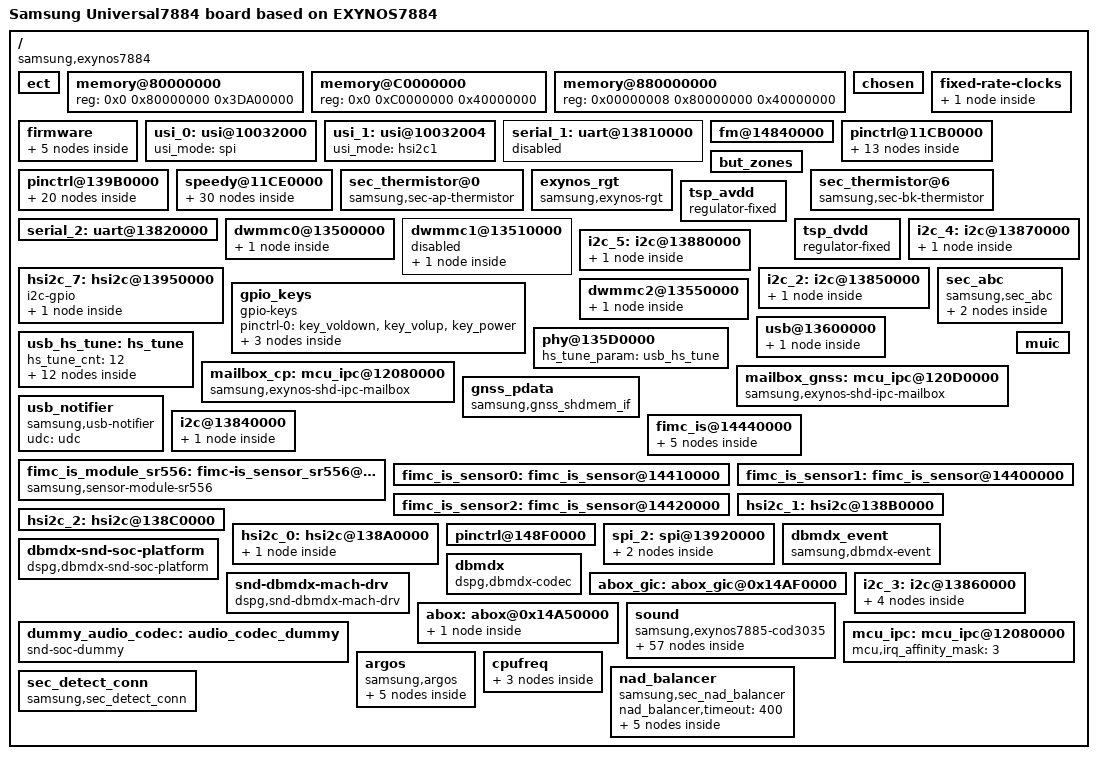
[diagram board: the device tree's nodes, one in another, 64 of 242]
/*
 * SAMSUNG UNIVERSAL7885 board device tree source
 *
 * Copyright (c) 2013 Samsung Electronics Co., Ltd.
 *		http://www.samsung.com
 *
 * This program is free software; you can redistribute it and/or modify
 * it under the terms of the GNU General Public License version 2 as
 * published by the Free Software Foundation.
*/

#include "exynos7884-rmem.dtsi"
#include "exynos7885.dtsi"
#include "display-lcd_gview2_common.dtsi"
#include "modem-s327ap-sipc-pdata.dtsi"
#include "battery_data_gview2lte_common.dtsi"
#include "exynos7885-jackpotlte_motor.dtsi"
#include "exynos7884-mali.dtsi"
/ {
	model = "Samsung Universal7884 board based on EXYNOS7884";
	compatible = "samsung,exynos7884", "samsung,Universal7884";

	ect {
		parameter_address = <0x90000000>;
		parameter_size = <0x19000>;
	};

	memory@80000000 {
		device_type = "memory";
		reg = <0x0 0x80000000 0x3DA00000>;
	};

	memory@C0000000 {
		device_type = "memory";
		reg = <0x0 0xC0000000 0x40000000>;
	};

	memory@880000000 {
		device_type = "memory";
		reg = <0x00000008 0x80000000 0x40000000>;
	};

	chosen {
		bootargs = "console=ram root=/dev/ram0 clk_ignore_unused androidboot.hardware=samsungexynos7885 androidboot.selinux=permissive ess_setup=0x86000000 androidboot.debug_level=0x4948";
		linux,initrd-start = <0x84000000>;
		linux,initrd-end = <0x840FFFFF>;
	};

	fixed-rate-clocks {
		oscclk {
			compatible = "samsung,exynos7885-oscclk";
			clock-frequency = <26000000>;
		};
	};

	firmware {
		android {
			compatible = "android,firmware";
			fstab {
				compatible = "android,fstab";
				system {
					compatible = "android,system";
					dev = "/dev/block/platform/13500000.dwmmc0/by-name/SYSTEM";
					type = "ext4";
					mnt_flags = "ro";
					fsmgr_flags = "wait,verify";
				};
				vendor {
					compatible = "android,vendor";
					dev = "/dev/block/platform/13500000.dwmmc0/by-name/VENDOR";
					type = "ext4";
					mnt_flags = "ro";
					fsmgr_flags = "wait,verify";
				};
				odm {
					compatible = "android,odm";
					dev = "/dev/block/platform/13500000.dwmmc0/by-name/ODM";
					type = "ext4";
					mnt_flags = "ro";
					fsmgr_flags = "wait,verify";
				};
			};
		};
	};

	/* USI MODE SETTINGS

	usi_mode = "hsi2c0" or "hsi2c1" or "spi" or "uart"
	or "hsi2c0_hsi2c1" or "uart_hsi2c1"
	*/
	usi_0: usi@10032000 {
		usi_mode = "spi";
		status = "okay";
	};

	usi_1: usi@10032004 {
		usi_mode = "hsi2c1";
		status = "okay";
	};

	serial_1: uart@13810000 {
		status = "disabled";
	};

	fm@14840000 {
		num-volume-level = <16>;
		val-vol-level = <0 11 16 23 32 45 64
				 90 128 181 256 362
				 512 724 1024 1400>;
	};

	pinctrl@11CB0000 {
		pmic_irq: pmic-irq {
			samsung,pins = "gpa2-0";
			samsung,pin-pud = <3>;
			samsung,pin-drv = <3>;
		};
	};

	pinctrl@139B0000 {
		/* Warm reset information from AP */
		pm_wrsti: pm-wrsti {
			samsung,pins = "gpg1-1";
			samsung,pin-con-pdn = <3>;
		};
	};

	pinctrl@139B0000 {
		/* SPI_FP */
		spi1_bus_inactive: spi1-bus-inactive {
			samsung,pins = "gpp6-0", "gpp6-1", "gpp6-3";
			samsung,pin-function = <1>;
			samsung,pin-pud = <0>;
			samsung,pin-drv = <2>;
		};
		spi1_miso_inactive: spi1-miso-inactive {
			samsung,pins = "gpp6-2";
			samsung,pin-function = <0>;
			samsung,pin-pud = <1>;
			samsung,pin-drv = <2>;
		};
		spi1_clk: spi1-clk {
			samsung,pins = "gpp6-0";
			samsung,pin-function = <2>;
			samsung,pin-pud = <1>;
			samsung,pin-drv = <2>;
		};
		spi1_cs: spi1-cs {
			samsung,pins = "gpp6-1";
			samsung,pin-function = <2>;
			samsung,pin-pud = <3>;
			samsung,pin-drv = <2>;
		};
		spi1_miso: spi1-miso {
			samsung,pins = "gpp6-2";
			samsung,pin-function = <2>;
			samsung,pin-pud = <0>;
			samsung,pin-drv = <2>;
		};
		spi1_mosi: spi1-mosi {
			samsung,pins = "gpp6-3";
			samsung,pin-function = <2>;
			samsung,pin-pud = <1>;
			samsung,pin-drv = <2>;
		};
	};

	but_zones: but_zones {
		#list-but-cells = <3>;
	};

	speedy@11CE0000 {
		status = "okay";
		audio_codec_cod3035x: cod3035x@03 {
			compatible = "codec,cod3035x";
			#sound-dai-cells = <1>;
			reg = <0x03>;
			i2c-speedy-address;
			vdd-supply = <&l36_reg>;
			pinctrl-names = "default";
			mic-bias1-voltage = <3>;
			mic-bias2-voltage = <1>;
			mic-bias-ldo-voltage = <3>;
			use-lassenA;
			use-btn-adc-mode;
			use-det-gdet-adc-mode = <1>;
			jack-imp-tuning = <7>;
			jackout-dbnc-time = <0x02>;
			io-channels = <&exynos_adc 3>,<&exynos_adc 7>;
			io-channel-names = "adc-ear","adc-gdet";
			#io-channel-cells = <1>;
			io-channel-ranges;
			but-zones-list = <&but_zones 226 0 366>,
					 <&but_zones 582 367 433>,
					 <&but_zones 115 434 605>,
					 <&but_zones 114 606 1261>;
			mic-adc-range = <1334>;
			btn-release-value = <1334>;
		};

		s2mpu08mfd@00 {
			compatible = "samsung,s2mpu08mfd";
			acpm-ipc-channel = <2>;
			i2c-speedy-address;
			s2mpu08,wakeup = "enabled";
			s2mpu08,irq-gpio = <&gpa2 0 0>;
			reg = <0x00>;
			interrupts = <2 0 0>;
			interrupt-parent = <&gpa2>;
			pinctrl-names = "default";
			pinctrl-0 = <&pmic_irq &pm_wrsti>;
			/* RTC: wtsr/smpl */
			wtsr_en = "enabled"; /* enable */
			smpl_en = "enabled"; /* enable */
			wtsr_timer_val = <3>;	/* 1000ms */
			smpl_timer_val = <0>;	/* 100ms */
			check_jigon = <0>; /* do not check jigon */
			/* RTC: If it's first boot, reset rtc to 1/1/2018 12:00:00(Mon) */
			init_time,sec = <0>;
			init_time,min = <0>;
			init_time,hour = <12>;
			init_time,mday = <1>;
			init_time,mon = <0>;
			init_time,year = <118>;
			init_time,wday = <1>;

			samsung,codec-interrupt = <&audio_codec_cod3035x>;

			regulators {
				b1_reg: BUCK1 {
					regulator-name = "vdd_mif";
					regulator-min-microvolt = <500000>;
					regulator-max-microvolt = <1100000>;
					regulator-always-on;
					regulator-ramp-delay = <12000>;
					regulator-initial-mode = <2>;
				};

				b2_reg: BUCK2 {
					regulator-name = "vdd_cpucl0";
					regulator-min-microvolt = <500000>;
					regulator-max-microvolt = <1300000>;
					regulator-always-on;
					regulator-ramp-delay = <12000>;
					regulator-initial-mode = <1>;
				};

				b3_reg: BUCK3 {
					regulator-name = "vdd_cpucl1_2";
					regulator-min-microvolt = <500000>;
					regulator-max-microvolt = <1300000>;
					regulator-always-on;
					regulator-ramp-delay = <12000>;
					regulator-initial-mode = <1>;
				};

				b4_reg: BUCK4 {
					regulator-name = "vdd_int";
					regulator-min-microvolt = <500000>;
					regulator-max-microvolt = <1200000>;
					regulator-always-on;
					regulator-ramp-delay = <12000>;
					regulator-initial-mode = <2>;
				};

				b5_reg: BUCK5 {
					regulator-name = "vdd_g3d";
					regulator-min-microvolt = <500000>;
					regulator-max-microvolt = <1300000>;
					regulator-always-on;
					regulator-ramp-delay = <12000>;
					regulator-initial-mode = <1>;
				};

				b6_reg: BUCK6 {
					regulator-name = "vdd2_mem";
					regulator-min-microvolt = <500000>;
					regulator-max-microvolt = <1300000>;
					regulator-always-on;
					regulator-ramp-delay = <12000>;
					regulator-initial-mode = <3>;
				};

				b7_reg: BUCK7 {
					regulator-name = "vdd_lldo";
					regulator-min-microvolt = <1200000>;
					regulator-max-microvolt = <1500000>;
					regulator-always-on;
					regulator-boot-on;
					regulator-ramp-delay = <12000>;
					regulator-initial-mode = <3>;
				};

				b8_reg: BUCK8 {
					regulator-name = "vdd_mldo";
					regulator-min-microvolt = <1800000>;
					regulator-max-microvolt = <2100000>;
					regulator-always-on;
					regulator-ramp-delay = <12000>;
					regulator-initial-mode = <3>;
				};

				l1_reg: LDO1 {
					regulator-name = "vdd_ldo1";
					regulator-min-microvolt = <700000>;
					regulator-max-microvolt = <1300000>;
					regulator-always-on;
					regulator-ramp-delay = <12000>;
					regulator-initial-mode = <3>;
				};

				l2_reg: LDO2 {
					regulator-name = "vqmmc";
					regulator-min-microvolt = <1800000>;
					regulator-max-microvolt = <3375000>;
					regulator-ramp-delay = <12000>;
				};

				l3_reg: LDO3 {
					regulator-name = "vdd_ldo3";
					regulator-min-microvolt = <800000>;
					regulator-max-microvolt = <1950000>;
					regulator-always-on;
					regulator-ramp-delay = <12000>;
					regulator-initial-mode = <3>;
				};

				l4_reg: LDO4 {
					regulator-name = "vdd_ldo4";
					regulator-min-microvolt = <500000>;
					regulator-max-microvolt = <1300000>;
					regulator-always-on;
					regulator-ramp-delay = <12000>;
					regulator-initial-mode = <1>;
				};

				l5_reg: LDO5 {
					regulator-name = "vdd_ldo5";
					regulator-min-microvolt = <800000>;
					regulator-max-microvolt = <1350000>;
					regulator-always-on;
					regulator-ramp-delay = <12000>;
					regulator-initial-mode = <1>;
				};

				l6_reg: LDO6 {
					regulator-name = "vdd_ldo6";
					regulator-min-microvolt = <800000>;
					regulator-max-microvolt = <1350000>;
					regulator-always-on;
					regulator-ramp-delay = <12000>;
					regulator-initial-mode = <1>;
				};

				l7_reg: LDO7 {
					regulator-name = "vdd_ldo7";
					regulator-min-microvolt = <800000>;
					regulator-max-microvolt = <1950000>;
					regulator-always-on;
					regulator-ramp-delay = <12000>;
					regulator-initial-mode = <1>;
				};

				l8_reg: LDO8 {
					regulator-name = "vdd_ldo8";
					regulator-min-microvolt = <500000>;
					regulator-max-microvolt = <1300000>;
					regulator-always-on;
					regulator-ramp-delay = <12000>;
					regulator-initial-mode = <1>;
				};

				l9_reg: LDO9 {
					regulator-name = "vdd_ldo9";
					regulator-min-microvolt = <500000>;
					regulator-max-microvolt = <1300000>;
					regulator-always-on;
					regulator-ramp-delay = <12000>;
					regulator-initial-mode = <1>;
				};

				l10_reg: LDO10 {
					regulator-name = "vdd_ldo10";
					regulator-min-microvolt = <500000>;
					regulator-max-microvolt = <1300000>;
					regulator-always-on;
					regulator-ramp-delay = <12000>;
					regulator-initial-mode = <1>;
				};

				l11_reg: LDO11 {
					regulator-name = "vdd_ldo11";
					regulator-min-microvolt = <500000>;
					regulator-max-microvolt = <1300000>;
					regulator-always-on;
					regulator-ramp-delay = <12000>;
					regulator-initial-mode = <1>;
				};

				l12_reg: LDO12 {
					regulator-name = "vdd_ldo12";
					regulator-min-microvolt = <800000>;
					regulator-max-microvolt = <1350000>;
					regulator-always-on;
					regulator-ramp-delay = <12000>;
					regulator-initial-mode = <1>;
				};

				l13_reg: LDO13 {
					regulator-name = "vdd_ldo13";
					regulator-min-microvolt = <800000>;
					regulator-max-microvolt = <1950000>;
					regulator-always-on;
					regulator-ramp-delay = <12000>;
					regulator-initial-mode = <1>;
				};

				l14_reg: LDO14 {
					regulator-name = "vdd_ldo14";
					regulator-min-microvolt = <1800000>;
					regulator-max-microvolt = <3375000>;
					regulator-always-on;
					regulator-ramp-delay = <12000>;
					regulator-initial-mode = <1>;
				};

				l33_reg: LDO33 {
					regulator-name = "vdd_ldo33";
					regulator-min-microvolt = <800000>;
					regulator-max-microvolt = <1950000>;
					regulator-always-on;
					regulator-ramp-delay = <12000>;
					regulator-initial-mode = <3>;
				};

				l34_reg: LDO34 {
					regulator-name = "vdd_ldo34";
					regulator-min-microvolt = <1800000>;
					regulator-max-microvolt = <3375000>;
					regulator-always-on;
					regulator-ramp-delay = <12000>;
					regulator-initial-mode = <3>;
				};

				l35_reg: LDO35 {
					regulator-name = "vmmc";
					regulator-min-microvolt = <1800000>;
					regulator-max-microvolt = <3000000>;
					regulator-ramp-delay = <12000>;
				};

				l36_reg: LDO36 {
					regulator-name = "vdd_ldo36";
					regulator-min-microvolt = <800000>;
					regulator-max-microvolt = <1950000>;
					regulator-always-on;
					regulator-ramp-delay = <12000>;
					regulator-initial-mode = <3>;
				};

				l37_reg: LDO37 {
					regulator-name = "vdd_ldo37";
					regulator-min-microvolt = <1800000>;
					regulator-max-microvolt = <3375000>;
					regulator-always-on;
					regulator-ramp-delay = <12000>;
					regulator-initial-mode = <3>;
				};
			};
		};
	};

	sec_thermistor@0 {
		compatible = "samsung,sec-ap-thermistor";
		status = "okay";

		adc_array = <165 173 181 189 197 205 213 221 229 237
			245 259 273 287 301 315 335 355 375 395
			415 437 459 482 504 527 546 565 584 603
			623 643 663 683 704 724 748 772 797 821
			845 874 904 933 962 992 1025 1059 1092 1126
			1159 1198 1236 1275 1313 1352 1389 1427 1464 1502
			1540 1583 1626 1669 1712 1756 1796 1836 1876 1916
			1956 1997 2038 2078 2119 2160 2204 2248 2292 2336
			2380 2420 2460 2499 2539 2579 2613 2646 2680 2714
			2748 2785 2822 2859 2896 2933 2965 2996 3028 3059
			3091 3119 3147 3175 3203 3231 3247 3263 3279 3295
			3311>;
		temp_array = <900 890 880 870 860 850 840 830 820 810
			800 790 780 770 760 750 740 730 720 710
			700 690 680 670 660 650 640 630 620 610
			600 590 580 570 560 550 540 530 520 510
			500 490 480 470 460 450 440 430 420 410
			400 390 380 370 360 350 340 330 320 310
			300 290 280 270 260 250 240 230 220 210
			200 190 180 170 160 150 140 130 120 110
			100 90 80 70 60 50 40 30 20 10
			0 (-10) (-20) (-30) (-40) (-50) (-60) (-70) (-80) (-90)
			(-100) (-110) (-120) (-130) (-140) (-150) (-160) (-170) (-180) (-190)
			(-200)>;
		io-channels = <&exynos_adc 0>;
		io-channel-names = "adc-ap-temp";
		io-channel-ranges;
	};

	sec_thermistor@6 {
		compatible = "samsung,sec-bk-thermistor";
		status = "okay";

		adc_array = <324 332 340 348 356 364 372 380 388 396
			404 418 432 446 460 474 494 514 534 554
			574 595 616 638 659 681 704 727 750 774
			797 821 845 869 893 918 945 973 1001 1028
			1056 1088 1120 1152 1184 1216 1254 1292 1330 1368
			1407 1447 1488 1529 1569 1610 1650 1690 1729 1769
			1809 1855 1900 1946 1991 2037 2078 2120 2161 2202
			2244 2286 2329 2371 2414 2457 2500 2543 2586 2629
			2672 2710 2749 2787 2826 2864 2895 2927 2958 2990
			3021 3055 3088 3122 3156 3190 3217 3245 3272 3300
			3328 3352 3376 3400 3424 3448 3461 3474 3487 3501
			3514>;
		temp_array = <900 890 880 870 860 850 840 830 820 810
			800 790 780 770 760 750 740 730 720 710
			700 690 680 670 660 650 640 630 620 610
			600 590 580 570 560 550 540 530 520 510
			500 490 480 470 460 450 440 430 420 410
			400 390 380 370 360 350 340 330 320 310
			300 290 280 270 260 250 240 230 220 210
			200 190 180 170 160 150 140 130 120 110
			100 90 80 70 60 50 40 30 20 10
			0 (-10) (-20) (-30) (-40) (-50) (-60) (-70) (-80) (-90)
			(-100) (-110) (-120) (-130) (-140) (-150) (-160) (-170) (-180) (-190)
			(-200)>;
		io-channels = <&exynos_adc 6>;
		io-channel-names = "adc-bk-temp";
		io-channel-ranges;
	};

	exynos_rgt {
		compatible = "samsung,exynos-rgt";
	};

	serial_2: uart@13820000 {
		status = "okay";
	};

	pinctrl@11CB0000 {
		dwmmc2_cd_ext_irq: dwmmc2_cd_ext_irq {
			samsung,pins = "gpa0-7";
			samsung,pin-function = <0xf>;
			samsung,pin-pud = <0>;
			samsung,pin-drv = <3>;
		};
	};

	dwmmc0@13500000 {
		status = "okay";
		num-slots = <1>;
		broken-cd;
		fixed_voltage;
		supports-highspeed;
		mmc-ddr-1_8v;
		mmc-hs200-1_8v;
		mmc-hs400-1_8v;
		supports-8bit;
		supports-cmd23;
		supports-erase;
		supports-hs400-enhanced-strobe;
		card-init-hwacg-ctrl;
		support-cmdq;
		qos-dvfs-level = <100000>;
		fifo-depth = <0x40>;
		non-removable;
		desc-size = <4>;
		card-detect-delay = <200>;
		samsung,dw-mshc-ciu-div = <3>;
		samsung,dw-mshc-txdt-crc-timer-fastlimit = <0x13>;
		samsung,dw-mshc-txdt-crc-timer-initval = <0x15>;
		samsung,dw-mshc-hs400-delay-line = <0x60>;
		samsung,dw-mshc-sdr-timing = <3 0 4 0>;
		samsung,dw-mshc-ddr-timing = <3 0 4 2>;
		samsung,dw-mshc-hs200-timing = <3 0 3 0>;
		samsung,dw-mshc-hs400-timing = <1 0 2 0>;
		samsung,dw-mshc-hs400-ulp-timing = <3 0 2 0>;

		num-ref-clks = <12>;
		ciu_clkin = <25 50 50 25 50 100 200 50 50 200 200 200>;

		/* Swapping clock drive strength */
		clk-drive-number = <4>;
		pinctrl-names = "default",
			"fast-slew-rate-1x",
			"fast-slew-rate-2x",
			"fast-slew-rate-3x",
			"fast-slew-rate-4x";
		pinctrl-0 = <&sd0_clk &sd0_cmd &sd0_rdqs &sd0_bus1 &sd0_bus4 &sd0_bus8>;
		pinctrl-1 = <&sd0_clk_fast_slew_rate_1x>;
		pinctrl-2 = <&sd0_clk_fast_slew_rate_2x>;
		pinctrl-3 = <&sd0_clk_fast_slew_rate_3x>;
		pinctrl-4 = <&sd0_clk_fast_slew_rate_4x>;
		slot@0 {
			reg = <0>;
			bus-width = <8>;
		};

	};

	dwmmc1@13510000 {
		status = "disabled";
		num-slots = <1>;
		channel = <1>;
		fixed_voltage;
		enable-cclk-on-suspend;
		caps-control;
		supports-highspeed;
		supports-4bit;
		keep-power-in-suspend;
		pm-ignore-notify;
		card-detect-type-external;
		use-broken-voltage;
		fifo-depth = <0x40>;
		card-detect-delay = <200>;
		qos-dvfs-level = <100000>;
		data-timeout = <200>;
		hto-timeout = <80>;
		samsung,dw-mshc-ciu-div = <3>;
		samsung,dw-mshc-sdr-timing = <3 0 2 0>;
		samsung,dw-mshc-ddr-timing = <3 0 2 1>;
		samsung,dw-mshc-sdr50-timing = <3 0 4 2>;
		samsung,dw-mshc-sdr104-timing = <3 0 3 0>;

		num-ref-clks = <9>;
		ciu_clkin = <25 50 50 25 50 100 200 50 50>;

		clk-drive-number = <4>;
		pinctrl-names = "default",
			"fast-slew-rate-1x",
			"fast-slew-rate-2x",
			"fast-slew-rate-3x",
			"fast-slew-rate-4x";
		pinctrl-0 = <&sd1_clk &sd1_cmd &sd1_bus1 &sd1_bus4>;
		pinctrl-1 = <&sd1_clk_fast_slew_rate_1x>;
		pinctrl-2 = <&sd1_clk_fast_slew_rate_2x>;
		pinctrl-3 = <&sd1_clk_fast_slew_rate_3x>;
		pinctrl-4 = <&sd1_clk_fast_slew_rate_4x>;
		slot@0 {
			reg = <0>;
			bus-width = <4>;
		};
	};

	tsp_avdd {
		compatible = "regulator-fixed";
		regulator-name = "tsp_avdd";
		regulator-min-microvolt = <1800000>;
		regulator-max-microvolt = <1800000>;
		gpio = <&gpg3 0 0>;
		enable-active-high;
		regulator-boot-on;
	};

	tsp_dvdd {
		compatible = "regulator-fixed";
		regulator-name = "tsp_dvdd";
		regulator-min-microvolt = <1800000>;
		regulator-max-microvolt = <1800000>;
		gpio = <&gpg3 3 0>;
		enable-active-high;
		regulator-boot-on;
	};

	i2c_4: i2c@13870000 {
		samsung,i2c-sda-delay = <100>;
		samsung,i2c-max-bus-freq = <400000>;
		status = "okay";
		touchscreen@49 {
			compatible = "stm,fts_touch";
			reg = <0x49>;
			pinctrl-names = "on_state", "off_state";
			pinctrl-0 = <&attn_irq>;
			pinctrl-1 = <&attn_input>;
			stm,irq_gpio = <&gpa0 0 0>;
			stm,irq_type = <8200>;
			stm,max_coords = <1920 1080>;	/* x y */
			stm,project_name = "view2", "T395";
			stm,regulator_dvdd = "tsp_dvdd";
			stm,regulator_avdd = "tsp_avdd";
			stm,firmware_name = "tsp_stm/fts6ct108_view2.fw";
			stm,factory_item_version = <2>;
			stm,tclm_level = <2>;
			stm,afe_base = <0x040B>;
		};
	};

	pinctrl@11CB0000 {
		attn_irq: attn-irq {
			samsung,pins = "gpa0-0";
			samsung,pin-function = <0xf>;
			samsung,pin-pud = <0>;
			samsung,pin-drv = <0>;
		};
		attn_input: attn-input {
			samsung,pins = "gpa0-0";
			samsung,pin-function = <0>;
			samsung,pin-pud = <1>;
		};
	};

	pinctrl@11CB0000 {
		main_grip1_int: main-grip1-int {
			samsung,pins = "gpa1-2";
			samsung,pin-function = <0xf>;
			samsung,pin-pud = <0>;
			samsung,pin-drv = <0>;
		};
	};

	pinctrl@139B0000 {
		sensor_en: sensor-en {
			samsung,pins = "gpg1-0";
			samsung,pin-function = <1>;
			samsung,pin-pud = <0>;
			samsung,pin-val = <1>;
			samsung,pin-drv = <0>;
		};

		acc_en: acc-en {
			samsung,pins = "gpg1-3";
			samsung,pin-function = <1>;
			samsung,pin-pud = <0>;
			samsung,pin-val = <1>;
			samsung,pin-drv = <0>;
		};

		grip_ldo: grip-ldo {
			samsung,pins = "gpp6-4";
			samsung,pin-function = <1>;
			samsung,pin-pud = <0>;
		};

		cfg_i2c: cfg-i2c {
			samsung,pins = "gpp4-2", "gpp4-3";
			samsung,pin-function = <2>;
			samsung,pin-pud = <0>;
			samsung,pin-drv = <0>;
		};

		acc_i2c: acc-i2c {
			samsung,pins = "gpp2-0", "gpp2-1";
			samsung,pin-function = <2>;
			samsung,pin-pud = <0>;
			samsung,pin-drv = <0>;
		};

		light_i2c: light-i2c {
			samsung,pins = "gpc2-6", "gpc2-7";
			samsung,pin-function = <2>;
			samsung,pin-pud = <0>;
			samsung,pin-drv = <0>;
		};
	};

	i2c_5:i2c@13880000 {
		status = "okay";
		#address-cells = <1>;
		#size-cells = <0>;
		samsung,i2c-sda-delay = <100>;
		pinctrl-names = "default";
		pinctrl-0 = <&cfg_i2c>;

		a96t3x6@20 {
			compatible = "a96t3x6";
			pinctrl-names = "default", "grip_ldo";
			pinctrl-0 = <&main_grip1_int &grip_ldo>;
			reg = <0x20>;
			interrupt-parent = <&gpa1>;
			interrupts = <2 0 0>;
			a96t3x6,irq_gpio = <&gpa1 2 0>;
			a96t3x6,ldo_en = <&gpp6 4 0>;
			/* temporary firmware */
			a96t3x6,fw_path = "abov/a96t346_gview2lte.fw";
			a96t3x6,firmup_cmd = <0x38>;
		};
	};

	hsi2c_7: hsi2c@13950000{
		compatible = "i2c-gpio";
		gpios = <&gpc2 6 0 /* sda */
                 &gpc2 7 0 /* scl */>;
		i2c-gpio,delay-us = <2>;
		status = "okay";
		#address-cells = <1>;
		#size-cells = <0>;
		pinctrl-names = "default", "sensor_en";
		pinctrl-0 = <&light_i2c &sensor_en>;

		cm3323-i2c@10 {
			compatible = "cm3323-i2c";
			reg = <0x10>;
			/* cm3323-i2c,vdd-supply = <>; */
			cm3323-i2c,vdd-alwayson = <1>;
			cm3323-i2c,vdd-ldo= <&gpg1 0 0x01>; /* SENSOR_LDO_EN */
		};
	};

	i2c_2: i2c@13850000 {
		samsung,i2c-sda-delay = <100>;
		samsung,i2c-max-bus-freq = <400000>;
		status = "okay";
		#address-cells = <1>;
		#size-cells = <0>;
		pinctrl-names = "default";
		pinctrl-0 = <&acc_i2c>;

		lis2ds@1D {
			compatible = "st,lis2ds";
			reg = <0x1D>;
			pinctrl-names = "default";
			pinctrl-0 = <&acc_int>;
			interrupt-parent = <&gpa0>;
			interrupts = <3 0 0>;
			st,orientation = <1 2 1 0 1 1 1 1 0>;
			st,drdy-int-pin = <1>;
			st,irq_gpio = <&gpa0 3 0x00>;
			st,vdd_ldo_pin = <&gpg1 3 0x01>; /* ACC_LDO_EN */
		};
	};

	dwmmc2@13550000 {
		status = "okay";
		num-slots = <1>;
		supports-4bit;
		supports-cmd23;
		supports-erase;
		supports-highspeed;
		sd-uhs-sdr50;
		sd-uhs-sdr104;
		card-detect-gpio;
		card-no-pre-powerup;
		bypass-for-allpass;
		card-init-hwacg-ctrl;
		skip-init-mmc-scan;
		qos-dvfs-level = <100000>;
		qos-sd3-dvfs-level = <267000>;
		fifo-depth = <0x40>;
		desc-size = <4>;
		card-detect-delay = <200>;
		data-timeout = <200>;
		hto-timeout = <80>;
		samsung,dw-mshc-ciu-div = <3>;
		clock-frequency = <800000000>;
		samsung,dw-mshc-sdr-timing = <3 0 2 0>;
		samsung,dw-mshc-ddr-timing = <3 0 2 1>;
		samsung,dw-mshc-sdr50-timing = <3 0 4 2>;
		samsung,dw-mshc-sdr104-timing = <3 0 3 0>;

		num-ref-clks = <9>;
		ciu_clkin = <25 50 50 25 50 100 200 50 50>;

		/* Swapping clock drive strength */
		clk-drive-number = <4>;
		pinctrl-names = "default",
			"fast-slew-rate-1x",
			"fast-slew-rate-2x",
			"fast-slew-rate-3x",
			"fast-slew-rate-4x";
		pinctrl-0 = <&sd2_clk &sd2_cmd &sd2_bus1 &sd2_bus4 &dwmmc2_cd_ext_irq>;
		pinctrl-1 = <&sd2_clk_fast_slew_rate_1x>;
		pinctrl-2 = <&sd2_clk_fast_slew_rate_2x>;
		pinctrl-3 = <&sd2_clk_fast_slew_rate_3x>;
		pinctrl-4 = <&sd2_clk_fast_slew_rate_4x>;

		card-detect = <&gpa0 7 0xf>;
		sec-sd-slot-type = <2>; /* Hybrid Tray SD slot */

		slot@0 {
			reg = <0>;
			bus-width = <4>;
			disable-wp;
		};

	};

	pinctrl@11CB0000 {
		key_power: key-power {
			samsung,pins = "gpa1-7";
			samsung,pin-function = <0xf>;
			samsung,pin-pud = <0>;
			samsung,pin-drv = <0>;
		};

		key_voldown: key-voldown {
			samsung,pins = "gpa1-6";
			samsung,pin-function = <0xf>;
			samsung,pin-pud = <0>;
			samsung,pin-drv = <0>;
		};

		key_volup: key-volup {
			samsung,pins = "gpa1-5";
			samsung,pin-function = <0xf>;
			samsung,pin-pud = <0>;
			samsung,pin-drv = <0>;
		};
	};

	gpio_keys {
		status = "okay";
		compatible = "gpio-keys";
		#address-cells = <1>;
		#size-cells = <0>;
		pinctrl-names = "default";
		pinctrl-0 = <&key_voldown &key_volup &key_power>;
		button@1 {
			label = "gpio-keys: KEY_VOLUMEDOWN";
			interrupts = <6 0 0>;
			interrupt-parent = <&gpa1>;
			linux,code = <114>;
			gpios = <&gpa1 6 0xf>;
		};
		button@2 {
			label = "gpio-keys: KEY_VOLUMEUP";
			interrupts = <5 0 0>;
			interrupt-parent = <&gpa1>;
			linux,code = <115>;
			gpios = <&gpa1 5 0xf>;
		};
		button@3 {
			label = "gpio-keys: KEY_POWER";
			interrupts = <7 0 0>;
			interrupt-parent = <&gpa1>;
			linux,code = <116>;
			gpios = <&gpa1 7 0xf>;
			gpio-key,wakeup = <1>;
		};

	};

	sec_abc {
		compatible = "samsung,sec_abc";
		status = "okay";

		gpu {
			gpu,label="GPU fault";
			gpu,threshold_count=<20>;
			gpu,threshold_time=<1200>;
		};
		aicl {
			aicl,label="battery aicl";
			aicl,threshold_count=<5>;
			aicl,threshold_time=<300>;
		};
	};

	usb@13600000 {
		status = "okay";
		dwc3 {
			dr_mode = "otg";
			maximum-speed = "high-speed";
			snps,quirk-frame-length-adjustment = <0x20>;
		};
	};

	phy@135D0000 {
		status = "okay";
		hs_tune_param = <&usb_hs_tune>;
	};

	usb_hs_tune:hs_tune {
		hs_tune_cnt = <12>;

		/* value = <device host> */
		hs_tune1 {
			tune_name = "tx_vref";
			tune_value = <0xd 0x1>;
		};

		hs_tune2 {
			tune_name = "tx_pre_emp";
			tune_value = <0x3 0x3>;
		};

		hs_tune3 {
			tune_name = "tx_pre_emp_plus";
			tune_value = <0x0 0x0>;
		};

		hs_tune4 {
			tune_name = "tx_res";
			tune_value = <0x3 0x3>;
		};

		hs_tune5 {
			tune_name = "tx_rise";
			tune_value = <0x3 0x3>;
		};

		hs_tune6 {
			tune_name = "tx_hsxv";
			tune_value = <0x3 0x3>;
		};

		hs_tune7 {
			tune_name = "tx_fsls";
			tune_value = <0x3 0x3>;
		};

		hs_tune8 {
			tune_name = "rx_sqrx";
			tune_value = <0x7 0x7>;
		};

		hs_tune9 {
			tune_name = "compdis";
			tune_value = <0x7 0x7>;
		};

		hs_tune10 {
			tune_name = "otg";
			tune_value = <0x2 0x2>;
		};

		hs_tune11 {
		/* true : 1, false: 0 */
		/* <enable_user_imp user_imp_value> */
			tune_name = "enable_user_imp";
			tune_value = <0x0 0x0>;
		};

		hs_tune12 {
		/* PHY clk : 1 , FREE clk : 0 */
			tune_name = "is_phyclock";
			tune_value = <0x1 0x1>;
		};
	};

	mailbox_cp: mcu_ipc@12080000 {
		compatible = "samsung,exynos-shd-ipc-mailbox";
		reg = <0x0 0x12080000 0x180>;
		mcu,name = "mcu_ipc_cp";
		mcu,id = <0>;
		interrupts = <0 55 0 >; /* MAILBOX_CP_TO_AP SPI Number */
	};

	mailbox_gnss: mcu_ipc@120D0000 {
		compatible = "samsung,exynos-shd-ipc-mailbox";
		reg = <0x0 0x120D0000 180>;
		mcu,name = "mcu_ipc_gnss";
		mcu,id = <1>;
		interrupts = <GIC_SPI 56 IRQ_TYPE_NONE>;
	};

	gnss_pdata {
		status = "okay";

		compatible = "samsung,gnss_shdmem_if";
		shmem,name = "KEPLER";
		shmem,device_node_name = "gnss_ipc";

		/* ACTIVE WATCHDOG WAKEUP */
		interrupts = <GIC_SPI 20 IRQ_TYPE_NONE>,
			     <GIC_SPI 165 IRQ_TYPE_NONE>,
			     <GIC_SPI 164 IRQ_TYPE_NONE>;
		interrupt-names = "ACTIVE", "WATCHDOG", "WAKEUP";

		memory-region = <&gnss_reserved>;
		mbox_info = <&mailbox_gnss>;

		mbx,int_ap2gnss_bcmd = <0>;
		mbx,int_ap2gnss_req_fault_info = <1>;
		mbx,int_ap2gnss_ipc_msg = <2>;
		mbx,int_ap2gnss_ack_wake_set = <3>;
		mbx,int_ap2gnss_ack_wake_clr = <4>;

		mbx,irq_gnss2ap_bcmd = <0>;
		mbx,irq_gnss2ap_rsp_fault_info = <1>;
		mbx,irq_gnss2ap_ipc_msg = <2>;
		mbx,irq_gnss2ap_req_wake_clr = <4>;

		mbx,reg_bcmd_ctrl = <0>, <1>, <2>, <3>;

		reg_rx_ipc_msg = <1 5>;
		reg_tx_ipc_msg = <1 4>;
		reg_rx_head = <1 3>;
		reg_rx_tail = <1 2>;
		reg_tx_head = <1 1>;
		reg_tx_tail = <1 0>;
		fault_info = <1 0x200000 0x180000>;

		shmem,ipc_offset = <0x380000>;
		shmem,ipc_size = <0x80000>;
		shmem,ipc_reg_cnt = <32>;

		/* Use the following value when can't boot with mailbox */
		shmem,boot_without_mbox = <1>; /* Default : 0 */
	};

	usb_notifier {
		compatible = "samsung,usb-notifier";
		udc = <&udc>;
	};

	pinctrl@11CB0000 {
		if_pmic_intb: if_pmic_intb {
			samsung,pins = "gpa2-3";
			samsung,pin-function = <0x0f>;
			samsung,pin-pud = <0>;
			samsung,pin-drv = <0>;
		};

		muic_int: muic-int {
			samsung,pins = "gpa1-1";
			samsung,pin-pud = <0>;
			samsung,pin-drv = <0>;
		};
	};

	i2c@13840000{
		status = "okay";
		max77865@66 {
			compatible = "maxim,max77865";
			pinctrl-names = "default";
			pinctrl-0 = <&if_pmic_intb &muic_int>;
			reg = <0x66>;
			max77865,irq-gpio = <&gpa2 3 1>;
			muic-universal,irq-gpio = <&gpa1 1 1>;
			muic-universal,chip_name = "max,max77865";
			max77865,wakeup;
			muic,undefined_range;
		};
	};

	muic {
		status = "okay";

		muic,support-list = "+OTG:GND",
				"-MHL:1K",
				"-VZW Accessory:28.7K",
				"-VZW Incompatible:34K",
				"+RDU TA:40.2K",
				"+HMT:49.9K",
				"-Audiodock:64.9K",
				"-USB LANHUB:80.07K",
				"-Charging Cable:102K",
				"-Game Pad:121K",
				"+TYPE1 Charger:200K",
				"+Jig USB Off:255K",
				"+Jig USB On:301K",
				"+Deskdock:365K",
				"+TYPE2 Charger:442K",
				"+Jig UART Off:523K",
				"+Jig UART On:619K",
				"+TA:OPEN",
				"+USB:OPEN",
				"+CDP:OPEN",
				"+Undefined Charging:XXX";
		muic,afcmode-tx = /bits/ 8 <0x08>;
		muic,qc-hv = /bits/ 8 <0x9>;
	};

	fimc_is@14440000 {
		pinctrl-names = "default","release";
		pinctrl-0 = <&fimc_is_mclk0_out &fimc_is_mclk1_out &fimc_is_mclk2_out>;
		pinctrl-1 = <>;

		vender {
			front_sensor_id = <209>; /* SENSOR_NAME_SR556 */
			use_module_check;
			check_sensor_vendor;
			// skip_cal_loading;

			max_camera_num = <2>;
			camera_info1 {				// 1 : front - SR556
				isp = <0>;			/* 0 : INT , 1 : EXT , 2 : SOC */
				cal_memory = <3>;		/* 0 : N , 1 : FROM , 2 : EEPROM , 3 : OTP  */
				read_version = <0>;		/* 0 : SYSFS , 1 : CAMON */
				core_voltage = <0>;		/* 0 : N , 1 : Y  */
				upgrade = <0>;			/* 0 : N , 1 : SYSFS , 2 : CAMON */
				companion = <0>;		/* 0 : N , 1 : Y  */
				ois = <0>;			/* 0 : N , 1 : Y  */
				valid = <1>;			/* 0 : INVALID, 1 : VALID */
				dual_open = <0>;		/* 0 : SINGLE_OPEN , 1 : DUAL_OPEN */
			};
		};

		fimc_is_dvfs {
			/* TODO: DVFS level set */
			#define DVFS_INT_L0 533000
			#define DVFS_INT_L1 333000
			#define DVFS_INT_L2 267000
			#define DVFS_INT_L3 133000
			#define DVFS_INT_L4 107000

			#define DVFS_CAM_L0 690000
			#define DVFS_CAM_L1 680000
			#define DVFS_CAM_L2 670000
			#define DVFS_CAM_L3 660000
			#define DVFS_CAM_L4 650000

			#define DVFS_MIF_L0 2093000
			#define DVFS_MIF_L1 2002000
			#define DVFS_MIF_L2 1794000
			#define DVFS_MIF_L3 1539000
			#define DVFS_MIF_L4 1352000
			#define DVFS_MIF_L5 1014000
			#define DVFS_MIF_L6 845000
			#define DVFS_MIF_L7 676000
			#define DVFS_MIF_L8 546000
			#define DVFS_MIF_L9 420000

			table0 {
				desc = "default";

				default_int = <DVFS_INT_L0>;
				default_cam = <DVFS_CAM_L0>;
				default_mif = <DVFS_MIF_L0>;
				default_i2c = <0>;

				front_preview_int = <DVFS_INT_L4>;
				front_preview_cam = <DVFS_CAM_L2>;
				front_preview_mif = <DVFS_MIF_L5>;
				front_preview_i2c = <0>;

				front_capture_int = <DVFS_INT_L4>;
				front_capture_cam = <DVFS_CAM_L2>;
				front_capture_mif = <DVFS_MIF_L5>;
				front_capture_i2c = <0>;

				front_video_int = <DVFS_INT_L4>;
				front_video_cam = <DVFS_CAM_L2>;
				front_video_mif = <DVFS_MIF_L5>;
				front_video_i2c = <0>;

				front_vt1_int = <DVFS_INT_L4>;
				front_vt1_cam = <DVFS_CAM_L2>;
				front_vt1_mif = <DVFS_MIF_L7>;
				front_vt1_i2c = <0>;

				front_vt2_int = <DVFS_INT_L4>;
				front_vt2_cam = <DVFS_CAM_L2>;
				front_vt2_mif = <DVFS_MIF_L7>;
				front_vt2_i2c = <0>;

				front_vt4_int = <DVFS_INT_L4>;
				front_vt4_cam = <DVFS_CAM_L2>;
				front_vt4_mif = <DVFS_MIF_L7>;
				front_vt4_i2c = <0>;

				preview_high_speed_fps_int = <DVFS_INT_L4>;
				preview_high_speed_fps_cam = <DVFS_CAM_L2>;
				preview_high_speed_fps_mif = <DVFS_MIF_L5>;
				preview_high_speed_fps_i2c = <0>;

				video_high_speed_60fps_int = <DVFS_INT_L4>;
				video_high_speed_60fps_cam = <DVFS_CAM_L2>;
				video_high_speed_60fps_mif = <DVFS_MIF_L5>;
				video_high_speed_60fps_i2c = <0>;

				video_high_speed_120fps_int = <DVFS_INT_L4>;
				video_high_speed_120fps_cam = <DVFS_CAM_L2>;
				video_high_speed_120fps_mif = <DVFS_MIF_L5>;
				video_high_speed_120fps_i2c = <0>;

				max_int = <DVFS_INT_L0>;
				max_cam = <DVFS_CAM_L0>;
				max_mif = <DVFS_MIF_L0>;
				max_i2c = <0>;
			};

			table1 {
				desc = "DVFS table for HAL3";

				default_int = <DVFS_INT_L0>;
				default_cam = <DVFS_CAM_L0>;
				default_mif = <DVFS_MIF_L0>;
				default_i2c = <0>;

				front_preview_int = <DVFS_INT_L4>;
				front_preview_cam = <DVFS_CAM_L2>;
				front_preview_mif = <DVFS_MIF_L5>;
				front_preview_i2c = <0>;

				front_capture_int = <DVFS_INT_L4>;
				front_capture_cam = <DVFS_CAM_L2>;
				front_capture_mif = <DVFS_MIF_L5>;
				front_capture_i2c = <0>;

				front_video_int = <DVFS_INT_L4>;
				front_video_cam = <DVFS_CAM_L2>;
				front_video_mif = <DVFS_MIF_L5>;
				front_video_i2c = <0>;

				front_vt1_int = <DVFS_INT_L4>;
				front_vt1_cam = <DVFS_CAM_L2>;
				front_vt1_mif = <DVFS_MIF_L5>;
				front_vt1_i2c = <0>;

				front_vt2_int = <DVFS_INT_L4>;
				front_vt2_cam = <DVFS_CAM_L2>;
				front_vt2_mif = <DVFS_MIF_L5>;
				front_vt2_i2c = <0>;

				front_vt4_int = <DVFS_INT_L4>;
				front_vt4_cam = <DVFS_CAM_L2>;
				front_vt4_mif = <DVFS_MIF_L5>;
				front_vt4_i2c = <0>;

				preview_high_speed_fps_int = <DVFS_INT_L4>;
				preview_high_speed_fps_cam = <DVFS_CAM_L2>;
				preview_high_speed_fps_mif = <DVFS_MIF_L5>;
				preview_high_speed_fps_i2c = <0>;

				video_high_speed_60fps_int = <DVFS_INT_L4>;
				video_high_speed_60fps_cam = <DVFS_CAM_L3>;
				video_high_speed_60fps_mif = <DVFS_MIF_L5>;
				video_high_speed_60fps_i2c = <0>;

				video_high_speed_120fps_int = <DVFS_INT_L4>;
				video_high_speed_120fps_cam = <DVFS_CAM_L2>;
				video_high_speed_120fps_mif = <DVFS_MIF_L5>;
				video_high_speed_120fps_i2c = <0>;

				max_int = <DVFS_INT_L0>;
				max_cam = <DVFS_CAM_L0>;
				max_mif = <DVFS_MIF_L0>;
				max_i2c = <0>;
			};
		};
	};

	fimc_is_module_sr556: fimc-is_sensor_sr556@40 {
		compatible = "samsung,sensor-module-sr556";

		pinctrl-names = "default", "pin1", "pin2", "release";
		pinctrl-0 = <&fimc_is_mclk0_out>;
		pinctrl-1 = <&fimc_is_mclk0_out>;
		pinctrl-2 = <&fimc_is_mclk0_fn>;
		pinctrl-3 = <>;

		position = <1>;	/* Rear:0. Front:1 */
		id = <1>; /* bns_id */
		mclk_ch = <1>;

		gpio_mclk = <&gpc0 0 0x1>;
		gpio_reset = <&gpf3 1 0x1>;	/* sensor reset VTCAM_RST_N*/
		gpio_cam_1p2_en = <&gpg1 2 0x1>; /*FCAM1_LDO_EN*/
		gpio_camio_1p8_cam_a2p8_en = <&gpp2 2 0x1>; /*VDD_VTCAM_1P8 & VDD_VTCAM_A2P8*/
		status = "okay";
	};

	#define SENSOR_SCENARIO_NORMAL		0
	#define SENSOR_SCENARIO_VISION		1
	#define SENSOR_SCENARIO_EXTERNAL	2
	#define SENSOR_SCENARIO_OIS_FACTORY	3
	#define SENSOR_SCENARIO_VIRTUAL		9
	#define FLITE_ID_NOTHING 100

	fimc_is_sensor0: fimc_is_sensor@14410000 {
		scenario = <SENSOR_SCENARIO_NORMAL>;	/* Normal, Vision, OIS etc */
		id = <1>;
		csi_ch = <1>;
		flite_ch = <FLITE_ID_NOTHING>;
		is_bns = <0>;
		is_flite = <0>;
		status = "okay";

		/*use_ssvc1_internal;*/
	};

	fimc_is_sensor1: fimc_is_sensor@14400000 {
		scenario = <SENSOR_SCENARIO_NORMAL>;	/* Normal, Vision, OIS etc */
		id = <0>;
		csi_ch = <0>;
		flite_ch = <FLITE_ID_NOTHING>;
		is_bns = <0>;
		is_flite = <0>;
		status = "okay";
	};

	fimc_is_sensor2: fimc_is_sensor@14420000 {
		scenario = <SENSOR_SCENARIO_NORMAL>;	/* Normal, Vision, OIS etc */
		id = <2>;
		csi_ch = <2>;
		flite_ch = <FLITE_ID_NOTHING>;
		is_bns = <0>;
		is_flite = <0>;
		status = "okay";
	};

	hsi2c_1: hsi2c@138B0000 {
		gpios = <&gpc1 2 0 &gpc1 3 0>;
		status = "okay";
		clock-frequency = <400000>;

		pinctrl-names = "on_i2c";
		pinctrl-0 = <&hs_i2c1_bus>;
	};

	hsi2c_2: hsi2c@138C0000 {
		gpios = <&gpc1 4 0 &gpc1 5 0>;
		status = "okay";
		clock-frequency = <400000>;

		pinctrl-names = "on_i2c";
		pinctrl-0 = <&hs_i2c2_bus>;
	};

	hsi2c_0: hsi2c@138A0000 {
		gpios = <&gpc1 0 0 &gpc1 1 0>;
		status = "okay";
		clock-frequency = <400000>;

		pinctrl-names = "on_i2c";
		pinctrl-0 = <&hs_i2c0_bus>;

		fimc-is-sr556@40 {
			compatible = "samsung,exynos5-fimc-is-cis-sr556";
			reg = <0x20>; /* 1 bit right shift */
			id = <1>; /* matching sensor id */
			sensor_f_number = <220>; /* f number 1.9 */
			setfile = "setC"; /* setC is for only Tablets(Landscape Device) */
		};
	};

	/* DISPAUD */
	pinctrl@148F0000 {
		/delete-node/ aud_fm_bus;
		/delete-node/ aud_fm_bus_idle;
	};

	pinctrl@139B0000 {
		spi2_bus: spi2-bus {
			samsung,pins = "gpc2-1", "gpc2-0";
			samsung,pin-function = <2>;
			samsung,pin-con-pdn = <3>;
			samsung,pin-pud = <1>;
			samsung,pin-pud-pdn = <0>;
			samsung,pin-drv = <0>;
		};

		spi2_bus_clk: spi2-bus-clk {
			samsung,pins = "gpc2-3";
			samsung,pin-function = <2>;
			samsung,pin-con-pdn = <3>;
			samsung,pin-pud = <0>;
			samsung,pin-pud-pdn = <0>;
			samsung,pin-drv = <0>;
			samsung,pin-val = <0>;
		};

		spi2_cs: spi2-cs {
			samsung,pins = "gpc2-2";
			samsung,pin-function = <2>;
			samsung,pin-con-pdn = <3>;
			samsung,pin-pud = <3>;
			samsung,pin-pud-pdn = <0>;
			samsung,pin-drv = <0>;
		};

		aud_dmic_on: aud_dmic_on {
			samsung,pins = "gpg2-1";
			samsung,pin-function = <1>;
			samsung,pin-con-pdn = <3>;
			samsung,pin-val = <1>;
		};

		aud_dmic_off: aud_dmic_off {
			samsung,pins = "gpg2-1";
			samsung,pin-function = <1>;
			samsung,pin-con-pdn = <3>;
			samsung,pin-val = <1>;
		};
	};

	spi_2: spi@13920000 {
		#address-cells = <1>;
		#size-cells = <0>;
		num-cs = <1>;

		/delete-property/ dma-mode;
		/delete-property/ dmas;
		/delete-property/ dma-names;

		pinctrl-names = "default";
		pinctrl-0 = <&spi2_bus &spi2_bus_clk &spi2_cs>;
		status = "okay";

		dbmd8_spi: dbmd8_interface@0 {
			compatible = "dspg,dbmd8-spi";
			reg = <0x0>;
			spi-max-frequency = <1000000>;
			read-chunk-size = <0x2000>;
			write-chunk-size = <0x40000>;

			interrupts = <2 0 0>;
			interrupt-parent = <&gpa0>;

			gpio-controller;
			#gpio-cells = <2>;

			controller-data {
				cs-gpio = <&gpc2 2 0>;
				samsung,spi-feedback-delay = <0>;
			};
		};
	};

	dbmdx_event {
		status = "okay";
		compatible = "samsung,dbmdx-event";
	};

	dbmdx-snd-soc-platform {
		compatible = "dspg,dbmdx-snd-soc-platform";
	};

	snd-dbmdx-mach-drv {
		compatible = "dspg,snd-dbmdx-mach-drv";
	};

	pinctrl@11CB0000 {
		dbmdx_int: dbmdx-int {
			samsung,pins = "gpa0-2";
			samsung,pin-function = <0xf>;
			samsung,pin-pud = <0>;
		};
		acc_int: acc-int {
			samsung,pins = "gpa0-3";
			samsung,pin-function = <0xf>;
			samsung,pin-pud = <0x1>;
			samsung,pin-drv = <0x1>;
		};
	};

	pinctrl@139B0000 {
		dbmdx_wakeup: dbmdx-wakeup {
			samsung,pins ="gpg2-3";
			samsung,pin-function = <1>;
			samsung,pin-pud = <3>;
			samsung,pin-con-pdn =<3>;
			samsung,pin-pud-pdn = <3>;
			samsung,pin-val = <1>;
		};

		dbmdx_reset: dbmdx-reset {
			samsung,pins ="gpg2-2";
			samsung,pin-function = <1>;
			samsung,pin-pud = <3>;
			samsung,pin-con-pdn =<3>;
			samsung,pin-pud-pdn = <3>;
			samsung,pin-val = <1>;
		};
	};

	dbmdx {
		status = "okay";
		compatible = "dspg,dbmdx-codec";

		pinctrl-names = "default";
		pinctrl-0 = <&dbmdx_wakeup &dbmdx_reset>;

		sv-gpio = <&gpa0 2 0>; /* VOICE_INT */
		wakeup-gpio = <&gpg2 3 0>; /* VOICE_WAKE */
		reset-gpio = <&gpg2 2 0>; /* VOICE_RST */
		auto_buffering = <1>;
		multi-interface-support = <1>;
		cd-interfaces = <&dbmd8_spi>;
		va-interfaces = <0 0 0 0>;
		feature-va; /* enable VA */
		va-firmware-name = "dbmd8_va_fw.bin";
		va-asrp-params-firmware-name = "dbmd8_va_asrp_fw.bin";
		va-config = <0x80000000
			     0x80000000
			     0x80000000
			     0x80290020
			     0x80093004
			     0x802210E1
			     0x80158F8F
			     0x801b0020
			     0x80230000
			     0x801A0011
			     0x8010700F
			     0x8aab0040
			     0x800C7530
			     0x80000000
			     0x80000000
			     0x80000000
			     0x80000000>;

		va-ns-config = <0x80000000 0x80000000 0x80000000 0x80000000 0x80000000
				0x80000000 0x80000000 0x80000000 0x80000000 0x80000000
				0x80000000 0x80000000 0x80000000 0x80000000 0x80000000
				0x8013FF20 0x8013FFF0 0x8013FFF2 0x8013FFF0 0x8013FFFF
				0x801A0011 0x801A0287 0x801A0011 0x801A0011 0x80340000
				0x80110E10 0x80340040 0x80110E10 0x80340040 0x80000000
				0x80111EEE 0x80000000 0x80111EEE 0x80000000 0x80000000
				0x80112EE2 0x80000000 0x80112EE2 0x80000000 0x80000000
				0x80113EEE 0x80000000 0x80113EEE 0x80000000 0x80000000
				0x80340243 0x80000000 0x80340243 0x80000000 0x80000000
				0x80000000 0x80000000 0x80000000 0x80000000 0x80000000
				0x80000000 0x80000000 0x80000000 0x80000000 0x80000000
				0x80000000 0x80000000 0x80000000 0x80000000 0x80000000
				0x80000000 0x80000000 0x80000000 0x80000000 0x80000000>;

		va-speeds = <0x0000 0 0 2000000
			     0x0000 0 0 4800000
			     0x0000 0 0 4800000 >;
		va-mic-config = <0xf021 0x5034 0x0008>;
		va-mic-mode = <2>;
/*
		digital_mic_digital_gain = <0x14>;
		analog_mic_analog_gain = <0x3>;
		analog_mic_digital_gain = <0x14>;
*/
		master-clk-rate = <32768>;
		/* constant-clk-rate = <32768>; */
		firmware_id = <0xdbd8>;
		use_gpio_for_wakeup = <1>; /* Use wakeup gpio */
		wakeup_set_value = <0>;  /* Value to write to wakeup gpio */
		auto_detection = <1>;
		detection_buffer_channels = <1>;
		min_samples_chunk_size = <128>;
		pcm_streaming_mode = <1>;
		boot_options = <0x220>; /* Verify chip id */
		send_uevent_on_detection = <1>;
		send_uevent_after_buffering = <0>;
		detection_after_buffering = <0>;
		va_backlog_length = <1802>;
		va_backlog_length_okg = <1000>;
		amodel_options = <0x1b>;
		va_ns_supported = <1>;
		va_ns-num_of_configs = <5>;
	};

	abox_gic: abox_gic@0x14AF0000 {
		status = "okay";
	};

	i2c_3: i2c@13860000 {
		status = "okay";
		tfa98xx_r1: tfa98xx@34 {
			compatible = "nxp,tfa98xx";
			#sound-dai-cells = <1>;
			reg = <0x34>;
		};
		tfa98xx_r2: tfa98xx@35 {
			compatible = "nxp,tfa98xx";
			#sound-dai-cells = <1>;
			reg = <0x35>;
		};
		tfa98xx_l1: tfa98xx@36 {
			compatible = "nxp,tfa98xx";
			#sound-dai-cells = <1>;
			reg = <0x36>;
		};
		tfa98xx_l2: tfa98xx@37 {
			compatible = "nxp,tfa98xx";
			#sound-dai-cells = <1>;
			reg = <0x37>;
		};
	};

	abox: abox@0x14A50000 {
		status = "okay";
		/* CAUTION:
		* "try to asrc off" quirk must be in dts.
		* It shouldn't be applied already audio tuned device,
		* because it changes delay and causes re-tune.
		*/
		/*
		* TODO: enable later
		*/
		/* quirks = "try to asrc off"; */

		pinctrl-names = "default", "idle";
		pinctrl-0 = <&aud_codec_mclk &aud_codec_bus &aud_spk_bus &aud_loopback_bus &aud_dmic_on>;
		pinctrl-1 = <&aud_codec_mclk_idle &aud_codec_bus_idle	&aud_spk_bus_idle &aud_loopback_bus_idle &aud_dmic_off>;

		ext_bin_0: ext_bin@0 {
			status = "disabled";
		};
	};

	dummy_audio_codec: audio_codec_dummy {
		status = "okay";
		compatible = "snd-soc-dummy";
	};

	sound {
		status = "okay";
		compatible = "samsung,exynos7885-cod3035";
		mic-bias-mode = <0 0 2 0>;
		dmic-path-en = <&gpg1 6 0>;
		clock-names = "xclkout";
		samsung,codec = <&abox &tfa98xx_r1 &tfa98xx_r2 &tfa98xx_l1 &tfa98xx_l2>;

		samsung,routing =  "VOUTPUT", "ABOX UAIF0 Playback",
				 "VOUTPUTCALL", "ABOX UAIF2 Playback",
				 "ABOX UAIF2 Capture", "VINPUTCALL",
				 "ABOX SPEEDY Capture", "VINPUTFM",
				 "SPK", "SPKR1 AIF Playback-b-34",
				 "SPKR1 AIF Playback-b-34", "ABOX UAIF3 Playback",
				 "ABOX UAIF3 Capture", "SPKR1 AIF Capture-b-34",
				 "SPK", "SPKR2 AIF Playback-b-35",
				 "SPKR2 AIF Playback-b-35", "ABOX UAIF3 Playback",
				 "ABOX UAIF3 Capture", "SPKR2 AIF Capture-b-35",
				 "SPK", "SPKL1 AIF Playback-b-36",
				 "SPKL1 AIF Playback-b-36", "ABOX UAIF3 Playback",
				 "ABOX UAIF3 Capture", "SPKL1 AIF Capture-b-36",
				 "SPK", "SPKL2 AIF Playback-b-37",
				 "SPKL2 AIF Playback-b-37", "ABOX UAIF3 Playback",
				 "ABOX UAIF3 Capture", "SPKL2 AIF Capture-b-37";

		rdma@0 {
			cpu {
				sound-dai = <&abox 0>;
			};
			codec {
				sound-dai = <&dummy_audio_codec>;
			};
		};
		rdma@1 {
			cpu {
				sound-dai = <&abox 1>;
			};
			codec {
				sound-dai = <&dummy_audio_codec>;
			};
		};
		rdma@2 {
			cpu {
				sound-dai = <&abox 2>;
			};
			codec {
				sound-dai = <&dummy_audio_codec>;
			};
		};
		rdma@3 {
			cpu {
				sound-dai = <&abox 3>;
			};
			codec {
				sound-dai = <&dummy_audio_codec>;
			};
		};
		rdma@4 {
			cpu {
				sound-dai = <&abox 4>;
			};
			codec {
				sound-dai = <&dummy_audio_codec>;
			};
		};
		rdma@5 {
			cpu {
				sound-dai = <&abox 5>;
			};
			codec {
				sound-dai = <&dummy_audio_codec>;
			};
		};
		rdma@6 {
			cpu {
				sound-dai = <&abox 6>;
			};
			codec {
				sound-dai = <&dummy_audio_codec>;
			};
		};
		rdma@7 {
			cpu {
				sound-dai = <&abox 7>;
			};
			codec {
				sound-dai = <&dummy_audio_codec>;
			};
		};
		wdma@0 {
			cpu {
				sound-dai = <&abox 8>;
			};
			codec {
				sound-dai = <&dummy_audio_codec>;
			};
		};
		wdma@1 {
			cpu {
				sound-dai = <&abox 9>;
			};
			codec {
				sound-dai = <&dummy_audio_codec>;
			};
		};
		wdma@2 {
			cpu {
				sound-dai = <&abox 10>;
			};
			codec {
				sound-dai = <&dummy_audio_codec>;
			};
		};
		wdma@3 {
			cpu {
				sound-dai = <&abox 11>;
			};
			codec {
				sound-dai = <&dummy_audio_codec>;
			};
		};
		wdma@4 {
			cpu {
				sound-dai = <&abox 12>;
			};
			codec {
				sound-dai = <&dummy_audio_codec>;
			};
		};
		uaif@0 {
			cpu {
				sound-dai = <&abox 13>;
			};
			codec {
				sound-dai = <&audio_codec_cod3035x 0>;
			};
		};
		uaif@1 {
			cpu {
				sound-dai = <&abox 14>;
			};
			codec {
				sound-dai = <&dummy_audio_codec>;
			};
		};
		uaif@2 {
			cpu {
				sound-dai = <&abox 15>;
			};
			codec {
				sound-dai = <&dummy_audio_codec>;
			};
		};
		uaif@3 {
			cpu {
				sound-dai = <&abox 16>;
			};
			codec {
				sound-dai = <&tfa98xx_r1 0 &tfa98xx_r2 0 &tfa98xx_l1 0 &tfa98xx_l2 0>;
			};
		};
		internal@0 {
			cpu {
				sound-dai = <&abox 17>;
			};
			codec {
				sound-dai = <&dummy_audio_codec>;
			};
		};
		speedy@0 {
			cpu {
				sound-dai = <&abox 18>;
			};
			codec {
				sound-dai = <&dummy_audio_codec>;
			};
		};
	};

	mcu_ipc: mcu_ipc@12080000 {
		mcu,irq_affinity_mask = <3>;
	};

	argos {
		compatible = "samsung,argos";
		#address-cells = <1>;
		/*  The device number should be assigned for each device, e.g. "boot_device@1" and "boot_device@2".
		 * Duplicated number is not allowed. Please refer the below example.
		 */

		/* Table Format should be
		 * <Throughput(Mbps) ARM_min ARM_max KFC_min KFC_max MIF INT Task IRQ HMP_boost>
		 * ARM_min : Big Core's minimum frequency lock. 0 means not set,
		 * ARM_max : Big Core's maximum frequency lock. 0 means not set,
		 * KFC_min : Little Core's minimum frequency lock. 0 means not set,
		 * KFC_max : Little Core's maximum frequency lock. 0 means not set,
		 * MIF : MIF frequency lock. 0 means not set,
		 * INT : INT frequency lock. 0 means not set,
		 * Task : 1 - Set task affinity lock.
		 *	0 - Not set or unlock,
		 *		Task affinity should be predefined driver's code.
		 * IRQ : 1 - Set irq affinity lock.
		 *       0 - Not set or unlock,
		 *		Task affinity should be predefined driver's code.
		 * HMP_boots : 1 - Increase hmp boosting count
		 *             0 - Decrease hmp boosting count
		 */

		 boot_device@1 {
		 net_boost,label="WIFI TX";
		 net_boost,node="wlan0";
		 net_boost,table_size = <2>;
		 net_boost,table= <
		 	60 1144000 0 676000 0 0 0 0 0 0
		 	120 1560000 0 1586000 0 0 267000 0 0 0
		 	>;
		 };

		 boot_device@2 {
		 net_boost,label="WIFI RX";
		 net_boost,node="wlan0";
		 net_boost,table_size = <1>;
		 net_boost,table= <
		 	250 1352000 0 1352000 0 0 0 0 0 0
		 	>;
		 };

		 boot_device@3 {
			net_boost,label="IPC";
			net_boost,node="rmnet0 rmnet1 rmnet2 rmnet3 rmnet4 rmnet5 rmnet6 rmnet7 umts_dm0";
			net_boost,table_size = <4>;
			net_boost,table= <
				1   0 0 0 0 0 0 0 1 0
				50  0 0 1170000 0 1144000 0 0 1 0
				100 0 0 1378000 0 1539000 0 0 1 0
				150 0 0 1586000 0 1794000 0 0 1 0
				>;
		};

		boot_device@4 {
			net_boost,label="CLAT";
			net_boost,node="clat clat4 v4-rmnet0 v4-rmnet1 v4-rmnet2 v4-rmnet3 v4-rmnet4 v4-rmnet5 v4-rmnet6 v4-rmnet7";
			net_boost,table_size = <3>;
			net_boost,table= <
				20  0 0 1170000 0 1539000 0 0 0 0
				50  0 0 1378000 0 1539000 0 0 0 0
				100 0 0 1586000 0 1794000 0 0 0 0
				>;
		};

		boot_device@5 {
			net_boost,label="USB";
			net_boost,node="rndis0";
			net_boost,table_size = <1>;
			net_boost,table= < 0 0 0 0 0 0 0 0 1 0 >;
		};

		/*
		 * boot_device@9 {
		 *	net_boost,label="WIFI RX";
		 *	net_boost,node="wlan0";
		 *	net_boost,table_size = <4>;
		 *	net_boost,table= <
		 *		5  2002000 0 1690000 0 0 0 0 0 0
		 *		10 2002000 0 1690000 0 0 0 0 0 0
		 *		20 2002000 0 1690000 0 845000 400000 1 1 1
		 *		30 2002000 0 1690000 0 1352000 533000 1 1 1
		 *		>;
		 * };
		 */
	};

	cpufreq {
		domain@1 {
			max-freq = <1560000>;

			dm-constraints {
				mif-perf {
					table = < 1560000 1794000
						1352000 1539000
						1144000 1014000
						936000  546000
						728000  420000>;
				};
			};
		};
	};

	nad_balancer {
		compatible = "samsung,sec_nad_balancer";
		status = "okay";

		nad_balancer,timeout = <400>;

			qos {
				cl0 {
					qos,label="LIT";
					qos,delay_time=<9>;
					qos,table_size=<12>;
					qos,table=<1586000 1482000 1352000 1248000 1144000 1014000 902000 839000 757000
						676000 546000 449000>;
				};

				cl1 {
					qos,label="BIG";
					qos,delay_time=<8>;
					qos,table_size=<11>;
					qos,table=<2184000 2080000 1976000 1872000 1768000 1664000 1560000 1352000 1144000
						936000 728000>;
				};

				mif {
					qos,label="MIF";
					qos,delay_time=<10>;
					qos,table_size=<8>;
					qos,table=<1794000 1539000 1352000 1014000 845000 676000 546000 420000>;
				};
			};

            sleep {
                /* per msec */
                sleep,suspend_threshold = <1000>;
                sleep,resume_threshold = <1000>;
            };
	};

	pinctrl@11CB0000 {
		sub_detect_conn_setting: sub_detect_conn_setting {
			samsung,pins = "gpa1-4";
			samsung,pin-function = <0xf>;
			samsung,pin-pud = <0>;
			samsung,pin-drv = <0>;
		};
	};

	sec_detect_conn {
		compatible = "samsung,sec_detect_conn";
		sec,det_conn_gpios = <&gpa1 4 0>;         /* SUB_DET */
		sec,det_conn_name = "SUB_CONNECT";
		sec,det_conn_irq_type = <3>; /* SUB_DETECT BOTH EDGE*/
		pinctrl-names = "default";
		pinctrl-0 = <&sub_detect_conn_setting>;
	};
};

